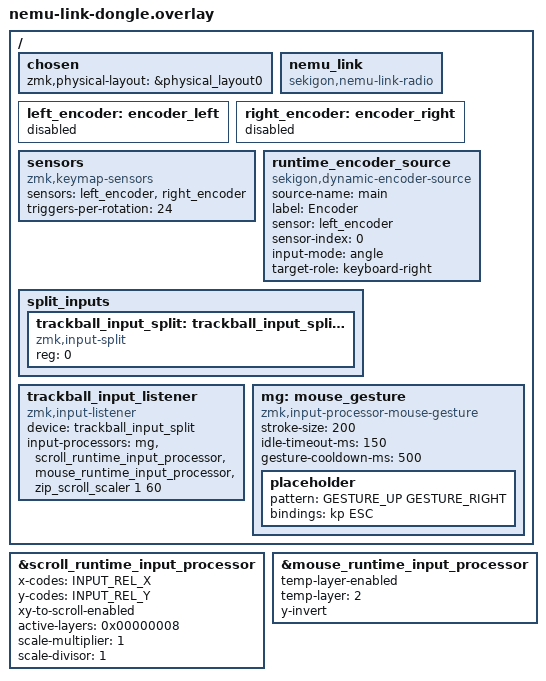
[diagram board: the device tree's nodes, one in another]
/* nemu-link-dongle 用拡張 overlay。
   dongle にはローカルの key matrix がないため、physical layout と
   ESB radio ノード、トラックボール入力の proxy+listener を定義する。
   kscan0 は dongle ボード定義の kscan-mock に解決される。 */
#include "../../../boards/shields/mona2/mona2_layouts.dtsi"
#include <dt-bindings/zmk/input_transform.h>
#include <input/processors.dtsi>
#include <input/processors/runtime-input-processor.dtsi>
#include <zephyr/dt-bindings/input/input-event-codes.h>
#include <dt-bindings/zmk/mouse-gesture.h>
#include <dt-bindings/zmk/keys.h>
#include <dt-bindings/zmk/pointing.h>

/ {
    chosen {
        zmk,physical-layout = &physical_layout0;
    };

    nemu_link {
        compatible = "sekigon,nemu-link-radio";
    };

    /* halves (mona2.dtsi) と同じ sensor index 空間・ノード名を dongle にも持たせる。
       dongle には実センサーが無いためプレースホルダにするが、Studio キーマップ同期の
       contract ハッシュ (generate-studio.py) に sensors の phandle 先ノード名が含まれるため
       mona2.dtsi と同じ encoder_left / encoder_right に揃える。 */
    left_encoder: encoder_left {
        status = "disabled";
    };
    right_encoder: encoder_right {
        status = "disabled";
    };

    sensors: sensors {
        compatible = "zmk,keymap-sensors";
        sensors = <&left_encoder &right_encoder>;
        triggers-per-rotation = <24>;
    };

    /* sekigon dynamic-encoder source (halves 側 mona2.dtsi と同一設定)。
       default-cw/ccw-binding を持たせないことで未設定時は keymap の静的
       sensor-bindings (&scroll_encoder / &inc_dec_kp) にフォールスルーし、
       Studio で明示設定したレイヤーのみ動的上書きされる。 */
    runtime_encoder_source: runtime_encoder_source {
        compatible = "sekigon,dynamic-encoder-source";
        source-name = "main";
        label = "Encoder";
        sensor = <&left_encoder>;
        sensor-index = <0>;
        input-mode = "angle";
        target-role = "keyboard-right";
    };

    /* 右 half の trackball_central_listener (listener index 0) から
       ESB 経由で届く入力イベントを受け取る proxy。
       wire reg は listener index と一致させる (既定の identity マッピング)。 */
    split_inputs {
        #address-cells = <1>;
        #size-cells = <0>;

        trackball_input_split: trackball_input_split@0 {
            compatible = "zmk,input-split";
            reg = <0>;
        };
    };

    /* proxy に届いたイベントを USB HID へ流す listener。
       ESB 時は右 half 側 (input_listener.c) が processor を全バイパスして
       raw イベントを流してくるため、右 half と同等の processor チェーンを
       ここで掛ける。dongle は keymap を持つので temp-layer 等も機能する。
       軸反転は mona2_r 側では mouse_runtime (実行時設定) に掛かっていた
       ため、ポインタ経路だけの反転として下で y-invert を付ける。
       スクロール経路には掛けない (raw Y が正方向)。 */
    trackball_input_listener: trackball_input_listener {
        compatible = "zmk,input-listener";
        device = <&trackball_input_split>;
        status = "okay";
        input-processors = <&mg &scroll_runtime_input_processor
                            &mouse_runtime_input_processor
                            &zip_scroll_scaler 1 60>;
    };

    /* mona2_r.overlay と同じ gesture / inertial scroll ノード */
    mg: mouse_gesture {
        compatible = "zmk,input-processor-mouse-gesture";
        #input-processor-cells = <0>;
        stroke-size = <200>;
        idle-timeout-ms = <150>;
        gesture-cooldown-ms = <500>;

        placeholder {
            pattern = <GESTURE_UP GESTURE_RIGHT>;
            bindings = <&kp ESC>;
        };
    };
    /* inertial_scroll は ZMK_MOUSE_GESTURE_RPC 配下でのみコンパイルされるため
       dongle では外す (モジュール既定でも off)。必要なら
       CONFIG_ZMK_MOUSE_GESTURE_RPC=y を追加して復帰可能。 */
};

/* mona2_r.overlay と同じ runtime processor 設定 */
&scroll_runtime_input_processor {
    x-codes = <INPUT_REL_X>;
    y-codes = <INPUT_REL_Y>;
    xy-to-scroll-enabled;
    active-layers = <0x00000008>; /* layer3 (SCRL_M) */
    scale-multiplier = <1>;
    scale-divisor = <1>;
};

&mouse_runtime_input_processor {
    /* 自動マウスレイヤー: MOUSE_M (2) */
    temp-layer-enabled;
    temp-layer = <2>;
    /* mona2_r では軸反転が runtime 設定側で掛かっていたため、
       ポインタ経路のみ Y を反転 (scroll 経路は raw が正方向) */
    y-invert;
};
